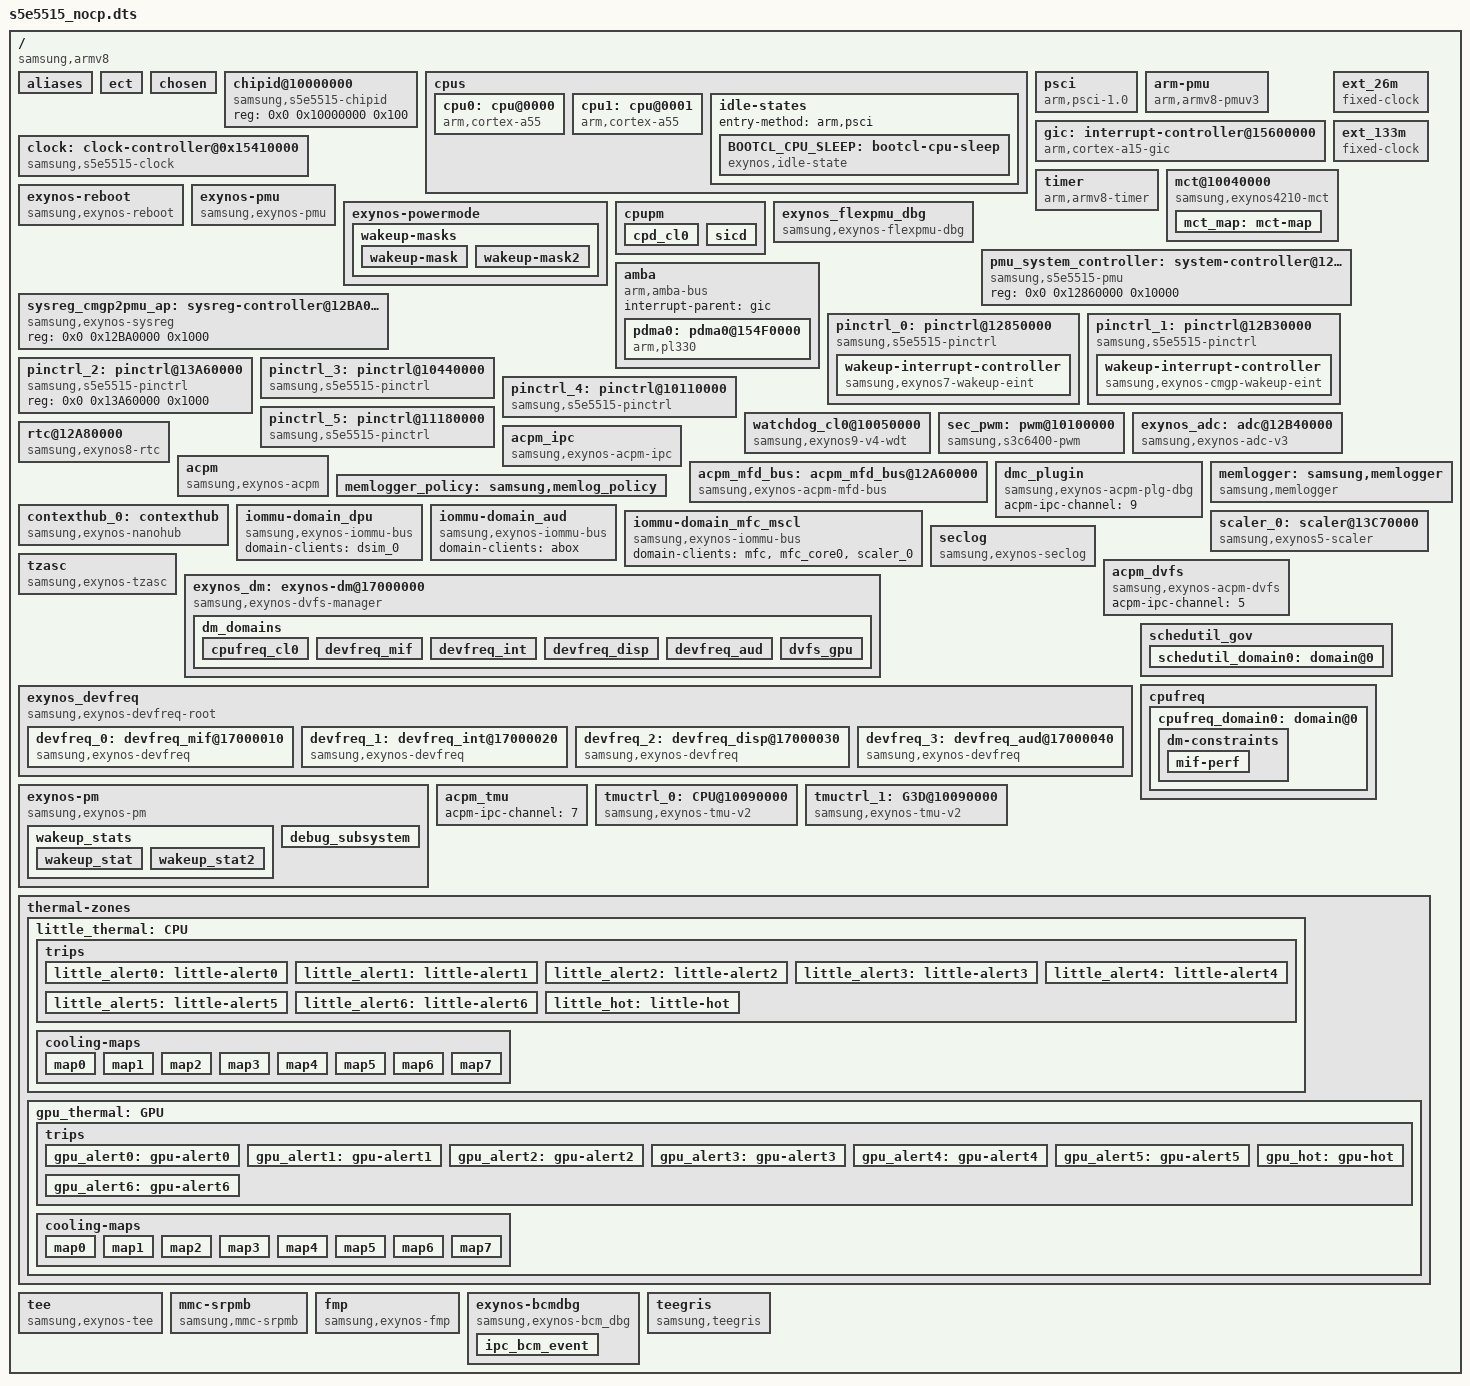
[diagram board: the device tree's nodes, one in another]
/*
 * SAMSUNG EXYNOS5515 SoC device tree source
 *
 * Copyright (c) 2017 Samsung Electronics Co., Ltd.
 *		http://www.samsung.com
 *
 * SAMSUNG EXYNOS5515 SoC device nodes are listed in this file.
 * EXYNOS5515 based board files can include this file and provide
 * values for board specfic bindings.
 *
 * This program is free software; you can redistribute it and/or modify
 * it under the terms of the GNU General Public License version 2 as
 * published by the Free Software Foundation.
 */
/dts-v1/;

#include "s5e5515-rmem_nocp.dtsi"
#include <dt-bindings/clock/s5e5515.h>
#include <dt-bindings/soc/samsung/exynos-bcm_dbg.h>
#include <dt-bindings/soc/samsung/s5e5515-dm.h>
#include <dt-bindings/soc/samsung/s5e5515-devfreq.h>
#include <dt-bindings/interrupt-controller/arm-gic.h>
#include <dt-bindings/interrupt-controller/s5e5515.h>
#include "s5e5515-dpu.dtsi"
#include "s5e5515-pinctrl.dtsi"
#include "s5e5515-usi.dtsi"
#include "s5e5515-usb.dtsi"
#include "s5e5515-sysmmu.dtsi"
#include "s5e5515-pm-domains.dtsi"
#include "s5e5515-mali.dtsi"
#include "s5e5515-audio.dtsi"
#include "s5e5515-debug.dtsi"
#include "s5e5515-mfc.dtsi"
#include "s5e5515-bts.dtsi"
#include "s5e5515-mmc.dtsi"
#include "s5e5515-lpd.dtsi"

/ {
	compatible = "samsung,armv8", "samsung,s5e5515";
	dtb-hw_rev = <0>;
	dtb-hw_rev_end = <255>;
	interrupt-parent = <&gic>;
	#address-cells = <2>;
	#size-cells = <1>;

	aliases {
		pinctrl0 = &pinctrl_0;
		pinctrl1 = &pinctrl_1;
		pinctrl2 = &pinctrl_2;
		pinctrl3 = &pinctrl_3;
		pinctrl4 = &pinctrl_4;
		pinctrl5 = &pinctrl_5;
		contexthub0 = &contexthub_0;

		scaler0 = &scaler_0;
	};

	ect {
		parameter_address = <0x90000000>;
		parameter_size = <0x32000>;
	};

	chosen: chosen {
		bootargs = "console=ram clocksource=arch_sys_counter clk_ignore_unused of_devlink=0 androidboot.hardware=s5e5515 firmware_class.path=/vendor/firmware androidboot.boot_devices=10500000.dwmmc0 sec_debug.cp=3 reserve-bcm=0xffffff80f8e00000 s3c2410_wdt.tmr_atboot=1 s3c2410_wdt.tmr_margin=80 rcupdate.rcu_expedited=1";
		linux,initrd-start = <0x84000000>;
		linux,initrd-end = <0x841FFFFF>;
	};

	chipid@10000000 {
		compatible = "samsung,s5e5515-chipid";
		reg = <0x0 0x10000000 0x100>;
	};

	cpus {
		#address-cells = <2>;
		#size-cells = <0>;

		cpu0: cpu@0000 {
			device_type = "cpu";
			compatible = "arm,cortex-a55", "arm,armv8";
			reg = <0x0 0x0000>;
			enable-method = "psci";
			cpu-idle-states = <&BOOTCL_CPU_SLEEP>;
		};
		cpu1: cpu@0001 {
			device_type = "cpu";
			compatible = "arm,cortex-a55", "arm,armv8";
			reg = <0x0 0x0001>;
			enable-method = "psci";
			cpu-idle-states = <&BOOTCL_CPU_SLEEP>;
		};

		idle-states {
			entry-method = "arm,psci";

			BOOTCL_CPU_SLEEP: bootcl-cpu-sleep {
				idle-state-name = "c2";
				compatible = "exynos,idle-state";
				arm,psci-suspend-param = <0x0010000>;
				entry-latency-us = <35>;
				exit-latency-us = <90>;
				min-residency-us = <750>;
				status = "okay";
			};
		};
	};

	psci {
		compatible = "arm,psci-1.0";
		method = "smc";
		cpu_suspend = <0xC4000001>;
		cpu_off = <0x84000002>;
		cpu_on = <0xC4000003>;
	};

	arm-pmu {
		compatible = "arm,armv8-pmuv3";
		interrupts = <0 INTREQ__CPUCL0_PMUIRQ_0 4>,
			      <0 INTREQ__CPUCL0_PMUIRQ_1 4>;
		interrupt-affinity = <&cpu0>, <&cpu1>;
	};

	gic:interrupt-controller@15600000 {
		compatible = "arm,cortex-a15-gic", "arm,cortex-a9-gic";
		#interrupt-cells = <3>;
		#address-cells = <0>;
		interrupt-controller;
		reg =	<0x0 0x15601000 0x1000>,
			<0x0 0x15602000 0x1000>,
			<0x0 0x15604000 0x2000>,
			<0x0 0x15606000 0x2000>;
	};

	clock: clock-controller@0x15410000 {
	       compatible = "samsung,s5e5515-clock";
	       reg = <0x0 0x15410000 0x8000>;
		#clock-cells = <1>;
		acpm-ipc-channel = <0>;
	};

	ext_26m: ext_26m {
		compatible = "fixed-clock";
		#clock-cells = <0>;
		clock-frequency = <26000000>;
		clock-output-names = "ext-26m";
	};

	ext_133m: ext_133m {
		compatible = "fixed-clock";
		#clock-cells = <0>;
		clock-frequency = <133250000>;
		clock-output-names = "ext-133m";
	};

	timer {
		compatible = "arm,armv8-timer";
		interrupts = <GIC_PPI 13
				(GIC_CPU_MASK_SIMPLE(8) | IRQ_TYPE_LEVEL_LOW)>,
			     <GIC_PPI 14
				(GIC_CPU_MASK_SIMPLE(8) | IRQ_TYPE_LEVEL_LOW)>,
			     <GIC_PPI 11
				(GIC_CPU_MASK_SIMPLE(8) | IRQ_TYPE_LEVEL_LOW)>,
			     <GIC_PPI 10
				(GIC_CPU_MASK_SIMPLE(8) | IRQ_TYPE_LEVEL_LOW)>;
	        clock-frequency = <26000000>;
	};

	mct@10040000 {
		compatible = "samsung,exynos4210-mct";
		reg = <0x0 0x10040000 0x800>;
		interrupt-controller;
		#interrupt-cells = <1>;
		interrupt-parent = <&mct_map>;
		interrupts =	<0>, <1>, <2>, <3>,
				<4>, <5>, <6>, <7>,
				<8>, <9>, <10>, <11>;
		clocks = <&clock OSCCLK>, <&clock GATE_MCT>;
		clock-names = "fin_pll", "mct";

		mct_map: mct-map {
			#interrupt-cells = <1>;
			#address-cells = <0>;
			#size-cells = <0>;
			interrupt-map = <0 &gic 0 INTREQ__MCT_G0 IRQ_TYPE_LEVEL_HIGH>,
					<1 &gic 0 INTREQ__MCT_G1 IRQ_TYPE_LEVEL_HIGH>,
					<2 &gic 0 INTREQ__MCT_G2 IRQ_TYPE_LEVEL_HIGH>,
					<3 &gic 0 INTREQ__MCT_G3 IRQ_TYPE_LEVEL_HIGH>,
					<4 &gic 0 INTREQ__MCT_L0 IRQ_TYPE_LEVEL_HIGH>,
					<5 &gic 0 INTREQ__MCT_L1 IRQ_TYPE_LEVEL_HIGH>,
					<6 &gic 0 INTREQ__MCT_L2 IRQ_TYPE_LEVEL_HIGH>,
					<7 &gic 0 INTREQ__MCT_L3 IRQ_TYPE_LEVEL_HIGH>,
					<8 &gic 0 INTREQ__MCT_L4 IRQ_TYPE_LEVEL_HIGH>,
					<9 &gic 0 INTREQ__MCT_L5 IRQ_TYPE_LEVEL_HIGH>,
					<10 &gic 0 INTREQ__MCT_L6 IRQ_TYPE_LEVEL_HIGH>,
					<11 &gic 0 INTREQ__MCT_L7 IRQ_TYPE_LEVEL_HIGH>;
		};
	};

	exynos-reboot {
		compatible = "samsung,exynos-reboot";
		samsung,syscon-phandle = <&pmu_system_controller>;
		shutdown-offset = <0x30C>;
		shutdown-trigger = <0x100>;
		reboot-offset = <0x3d00>;
		reboot-trigger = <0x2>;
		reboot-cmd-offset = <0x0810>;
	};

	exynos-pmu {
		compatible = "samsung,exynos-pmu";
		samsung,syscon-phandle = <&pmu_system_controller>;
		reg = <0x0 0x12860000 0x10000>;
		reg-names = "pmu_alive";
	};

	exynos-powermode {
		wakeup-masks {
			/*
			 * wakeup_mask configuration (Only SICD use wakeup-mask)
			 *      SICD          SICD_CPD      AFTR          STOP
			 *      LPD           LPA           ALPA          DSTOP
			 *      SLEEP         SLEEP_VTS_ON  SLEEP_AUD_ON  FAPO
			 *      USB_L2        SYS_SLEEP_HSI2ON
			 */
			wakeup-mask {
				mask = <0x07F3BFFF>, <0x0>,        <0x0>,        <0x0>,
				       <0x0>,        <0x0>,        <0x0>,        <0x0>,
				       <0x0>,        <0x0>,        <0x0>,        <0x0>,
				       <0x0>,        <0x0>;
				reg-offset = <0x3C44>;
			};
			wakeup-mask2 {
				mask = <0x00666807>, <0x0>,        <0x0>,        <0x0>,
				       <0x0>,        <0x0>,        <0x0>,        <0x0>,
				       <0x0>,        <0x0>,        <0x0>,        <0x0>,
				       <0x0>,        <0x0>;
				reg-offset = <0x3C64>;
			};
		};
	};

	cpupm {
		#define POWERMODE_TYPE_CLUSTER  0
		#define POWERMODE_TYPE_SYSTEM   1

		cpd_cl0 {
			device_type = "cpupm";
			target-residency = <3000>;
			psci-index = <128>;
			type = <POWERMODE_TYPE_CLUSTER>;
			siblings = "0-1";
		};

		sicd {
			device_type = "cpupm";
			target-residency = <3000>;
			psci-index = <256>;
			type = <POWERMODE_TYPE_SYSTEM>;
			siblings = "0-1";
			entry-allowed = "0-1";
			system-idle;
		};
	};

	exynos_flexpmu_dbg {
		compatible = "samsung,exynos-flexpmu-dbg";
		#address-cells = <2>;
		#size-cells = <1>;
		data-base = <0x12D1FB00>;
		data-size = <0x400>;
		mid-dvs-en = <0>;
		reg = <0x0 0x12a80000 0x1000>;
	};

	pmu_system_controller: system-controller@12860000 {
	       compatible = "samsung,s5e5515-pmu", "syscon";
	       reg = <0x0 0x12860000 0x10000>;
       };

	sysreg_cmgp2pmu_ap: sysreg-controller@12BA0000 {
		compatible = "samsung,exynos-sysreg", "syscon";
		reg = <0x0 0x12BA0000 0x1000>;
	};

	/* DMA */
	amba {
		#address-cells = <2>;
		#size-cells = <1>;
		compatible = "arm,amba-bus";
		interrupt-parent = <&gic>;
		ranges;

		pdma0: pdma0@154F0000 {
			compatible = "arm,pl330", "arm,primecell";
			reg = <0x0 0x154F0000 0x1000>;
			interrupts = <0 INTREQ__PDMA_irq_u1 IRQ_TYPE_LEVEL_HIGH>;
			clocks = <&clock GATE_PDMA_CORE_QCH>;
			clock-names = "apb_pclk";
			#dma-cells = <1>;
			#dma-channels = <4>;
			#dma-requests = <32>;
			#dma-multi-irq = <1>;
			dma-arwrapper = <0x154F4400>,
					<0x154F4420>,
					<0x154F4440>,
					<0x154F4460>;
			dma-awwrapper = <0x154F4404>,
					<0x154F4424>,
					<0x154F4444>,
					<0x154F4464>;
			dma-instwrapper = <0x154F4480>;
			dma-mask-bit = <36>;
			coherent-mask-bit = <36>;
		};
	};

	/* ALIVE */
	pinctrl_0: pinctrl@12850000 {
		compatible = "samsung,s5e5515-pinctrl";
		reg = <0x0 0x12850000 0x1000>;
		interrupts =  <0 INTREQ__ALIVE_EXT_INT0 IRQ_TYPE_LEVEL_HIGH>,
						<0 INTREQ__ALIVE_EXT_INT1 IRQ_TYPE_LEVEL_HIGH>,
						<0 INTREQ__ALIVE_EXT_INT2 IRQ_TYPE_LEVEL_HIGH>,
						<0 INTREQ__ALIVE_EXT_INT3 IRQ_TYPE_LEVEL_HIGH>,
						<0 INTREQ__ALIVE_EXT_INT4 IRQ_TYPE_LEVEL_HIGH>,
						<0 INTREQ__ALIVE_EXT_INT5 IRQ_TYPE_LEVEL_HIGH>,
						<0 INTREQ__ALIVE_EXT_INT6 IRQ_TYPE_LEVEL_HIGH>,
						<0 INTREQ__ALIVE_EXT_INT7 IRQ_TYPE_LEVEL_HIGH>,
						<0 INTREQ__ALIVE_EXT_INT8 IRQ_TYPE_LEVEL_HIGH>,
						<0 INTREQ__ALIVE_EXT_INT9 IRQ_TYPE_LEVEL_HIGH>,
						<0 INTREQ__ALIVE_EXT_INT10 IRQ_TYPE_LEVEL_HIGH>,
						<0 INTREQ__ALIVE_EXT_INT11 IRQ_TYPE_LEVEL_HIGH>,
						<0 INTREQ__ALIVE_EXT_INT12 IRQ_TYPE_LEVEL_HIGH>,
						<0 INTREQ__ALIVE_EXT_INT13 IRQ_TYPE_LEVEL_HIGH>,
						<0 INTREQ__ALIVE_EXT_INT14 IRQ_TYPE_LEVEL_HIGH>;

		wakeup-interrupt-controller {
			compatible = "samsung,exynos7-wakeup-eint";
		};

	};

	/* CMGP_ALIVE */
	pinctrl_1: pinctrl@12B30000{
		compatible = "samsung,s5e5515-pinctrl";
		reg = <0x0 0x12B30000 0x1000>;
		interrupts = <0 INTREQ__CMGP_EXT_INTM00 IRQ_TYPE_LEVEL_HIGH>,
					<0 INTREQ__CMGP_EXT_INTM01 IRQ_TYPE_LEVEL_HIGH>,
					<0 INTREQ__CMGP_EXT_INTM02 IRQ_TYPE_LEVEL_HIGH>,
					<0 INTREQ__CMGP_EXT_INTM03 IRQ_TYPE_LEVEL_HIGH>,
					<0 INTREQ__CMGP_EXT_INTM04 IRQ_TYPE_LEVEL_HIGH>,
					<0 INTREQ__CMGP_EXT_INTM05 IRQ_TYPE_LEVEL_HIGH>,
					<0 INTREQ__CMGP_EXT_INTM06 IRQ_TYPE_LEVEL_HIGH>,
					<0 INTREQ__CMGP_EXT_INTM07 IRQ_TYPE_LEVEL_HIGH>,
					<0 INTREQ__CMGP_EXT_INTM08 IRQ_TYPE_LEVEL_HIGH>,
					<0 INTREQ__CMGP_EXT_INTM09 IRQ_TYPE_LEVEL_HIGH>,
					<0 INTREQ__CMGP_EXT_INTM10 IRQ_TYPE_LEVEL_HIGH>,
					<0 INTREQ__CMGP_EXT_INTM11 IRQ_TYPE_LEVEL_HIGH>,
					<0 INTREQ__CMGP_EXT_INTM12 IRQ_TYPE_LEVEL_HIGH>,
					<0 INTREQ__CMGP_EXT_INTM13 IRQ_TYPE_LEVEL_HIGH>,
					<0 INTREQ__CMGP_EXT_INTM14 IRQ_TYPE_LEVEL_HIGH>,
					<0 INTREQ__CMGP_EXT_INTM15 IRQ_TYPE_LEVEL_HIGH>,
					<0 INTREQ__CMGP_EXT_INTM16 IRQ_TYPE_LEVEL_HIGH>,
					<0 INTREQ__CMGP_EXT_INTM17 IRQ_TYPE_LEVEL_HIGH>,
					<0 INTREQ__CMGP_EXT_INTM18 IRQ_TYPE_LEVEL_HIGH>,
					<0 INTREQ__CMGP_EXT_INTM19 IRQ_TYPE_LEVEL_HIGH>,
					<0 INTREQ__CMGP_EXT_INTM20 IRQ_TYPE_LEVEL_HIGH>,
					<0 INTREQ__CMGP_EXT_INTM21 IRQ_TYPE_LEVEL_HIGH>,
					<0 INTREQ__CMGP_EXT_INTM22 IRQ_TYPE_LEVEL_HIGH>,
					<0 INTREQ__CMGP_EXT_INTM23 IRQ_TYPE_LEVEL_HIGH>,
					<0 INTREQ__CMGP_EXT_INTM24 IRQ_TYPE_LEVEL_HIGH>,
					<0 INTREQ__CMGP_EXT_INTM25 IRQ_TYPE_LEVEL_HIGH>,
					<0 INTREQ__CMGP_EXT_INTM26 IRQ_TYPE_LEVEL_HIGH>;

		samsung,syscon-phandle = <&sysreg_cmgp2pmu_ap>;
		wakeup-interrupt-controller {
			compatible = "samsung,exynos-cmgp-wakeup-eint";
		};
	};

	/* DPU */
	pinctrl_2: pinctrl@13A60000{
		compatible = "samsung,s5e5515-pinctrl";
		reg = <0x0 0x13A60000 0x1000>;
	};

	/* FSYS */
	pinctrl_3: pinctrl@10440000 {
		compatible = "samsung,s5e5515-pinctrl";
		reg = <0x0 0x10440000 0x1000>;
		interrupts = <0 INTREQ__GPIO_FSYS IRQ_TYPE_LEVEL_HIGH>;
	};

	/* PERI */
	pinctrl_4: pinctrl@10110000 {
		compatible = "samsung,s5e5515-pinctrl";
		reg = <0x0 0x10110000 0x1000>;
		interrupts = <0 INTREQ__GPIO_PERI IRQ_TYPE_LEVEL_HIGH>;
	};

	/* VTS */
	pinctrl_5: pinctrl@11180000{
		compatible = "samsung,s5e5515-pinctrl";
		reg = <0x0 0x11180000 0x1000>;
		interrupts = <0 GPIO_INTREQ_VTS IRQ_TYPE_LEVEL_HIGH>;
	};

	watchdog_cl0@10050000 {
		compatible = "samsung,exynos9-v4-wdt";
		reg = <0x0 0x10050000 0x100>;
		interrupts = <0 INTREQ__WDT0 IRQ_TYPE_LEVEL_HIGH>;
		clocks = <&clock OSCCLK>, <&clock GATE_WDT_CLUSTER0>;
		clock-names = "rate_watchdog", "gate_watchdog";
		timeout-sec = <30>;
		shutdown_wdt_timeout = <30>;
		samsung,syscon-phandle = <&pmu_system_controller>;
		index = <0>; /* if little cluster then index is 0 */
		status = "okay";
	};

	sec_pwm: pwm@10100000 {
		compatible = "samsung,s3c6400-pwm";
		reg = <0x0 0x10100000 0x1000>;
		samsung,pwm-outputs = <0>, <1>, <2>, <3>, <4>;
		#pwm-cells = <3>;
		clocks = <&clock GATE_PWM_MOTOR>, <&clock OSCCLK>;
		clock-names = "pwm_pclk", "pwm_sclk";
		status = "okay";
	};

	exynos_adc: adc@12B40000 {
		compatible = "samsung,exynos-adc-v3";
		reg = <0x0 0x12B40000 0x100>;
		interrupts = <0 INTREQ__ADC_CMGP2AP IRQ_TYPE_LEVEL_HIGH>;
		#io-channel-cells = <1>;
		io-channel-ranges;
		clocks = <&clock GATE_ADC_CMGP_S0>;
		clock-names = "gate_adcif";
	};

	rtc@12A80000 {
		compatible = "samsung,exynos8-rtc";
		reg = <0x0 0x12A80000 0x100>;
		interrupts = <0 INTREQ__RTC_ALARM_INT IRQ_TYPE_LEVEL_HIGH>, <0 INTREQ__RTC_TIC_INT_0 IRQ_TYPE_LEVEL_HIGH>;
	};

	acpm_ipc {
		compatible = "samsung,exynos-acpm-ipc";
		#address-cells = <2>;
		#size-cells = <1>;
		interrupts = <GIC_SPI INTREQ__MAILBOX_APM2AP IRQ_TYPE_LEVEL_HIGH>;	/* AP2APM MAILBOX SPI NUM*/
		reg = <0x0 0x12900000 0x1000>,		/* AP2APM MAILBOX */
			<0x0 0x12D00000 0x22000>;	/* APM SRAM */
		initdata-base = <0x6900>;		/* AP share */
		num-timestamps = <32>;
		debug-log-level = <0>;
		logging-period = <500>;
		dump-base = <0x12D03000>;
		dump-size = <0x1F000>;			/* 136KB - 12KB(SACPM) = 124KB */
		dram-dump-base = <0x90009000>;
	};

	acpm {
		compatible = "samsung,exynos-acpm";
		#address-cells = <2>;
		#size-cells = <1>;
		acpm-ipc-channel = <4>;
		use-plugin-library;
		fvmap_offset = <0x20000>;		/* FVMAP: 0x20000*/
		reg = <0x0 0x12830000 0x1000>;		/* TIMER_APM */
		reg-names = "timer_apm";
		peritimer-cnt = <0xFFFF>;
	};

	acpm_mfd_bus: acpm_mfd_bus@12A60000 {
		compatible = "samsung,exynos-acpm-mfd-bus";
		status = "okay";
	};

	dmc_plugin {
		compatible = "samsung,exynos-acpm-plg-dbg";
		acpm-ipc-channel = <9>;
	};

	memlogger: samsung,memlogger {
		compatible = "samsung,memlogger";
		memory-region = <&memlog_mem>;
		samsung,bl-node = <&memlog_bl_base>;
	};

	memlogger_policy: samsung,memlog_policy {
		samsung,log-level = <4>;
		samsung,file-default-status = <1>;
		samsung,mem-constraint = <0>;
		samsung,mem-to-file-allow = <1>;
	};

	contexthub_0: contexthub {
		compatible = "samsung,exynos-nanohub";
		memory-region = <&chub_rmem &lpd_rmem>;
		/* INTREQ MAILBOX_AP2CHUB */
		interrupts = <0 58 IRQ_TYPE_LEVEL_HIGH>, <0 87 IRQ_TYPE_LEVEL_HIGH>;
		reg =	<0x0 0x12A30000 0x200>,
		        <0x0 0x12A20000 0x200>,
			<0x0 0x10D00000 0x200000>,
			<0x0 0x10CD0000 0x100>,
			<0x0 0x12863300 0x10>,
			<0x0 0x10C20000 0x20>,
			<0x0 0x10C30000 0x20>,
			<0x0 0x10C40000 0x4000>,
			<0x0 0x10110000 0x2000>;
			/*<0x0 0x10C00000 0x1820>,
			<0x0 0x10C40000 0x3030>,
			<0x0 0x10C70000 0x10>,
			<0x0 0x10C60000 0x10>,
			<0x0 0x10C90000 0x50>,
			<0x0 0x10CA0000 0xF0>,
			<0x0 0x10CB0000 0xF0>,
			<0x0 0x10CC0000 0xF0>;*/
		reg-names = "mailbox", "mailbox_apm_chub", "sram", "dumpgpr", "chub_reset",
			    "baaw_c_chub", "baaw_d_chub", "sysreg_chub", "gpio_peri";
			    /*"chub_dump_cmu", "chub_dump_sys",
			    "chub_dump_wdt", "chub_dump_timer",
			    "chub_dump_pwm", "chub_dump_usi0",
			    "chub_dump_usi1", "chub_dump_usi2";*/
		/* BAAW_C_CHUB to access mailbox, RTC, CMGP */
		baaw,baaw_c_chub = <0x40300 0x40800 0x12900 0x80000003>;
				   /* start    end    remap */
		baaw,baaw_d_chub = < 0x50000 0x50001 0x10000 0x80000003 /* chip id */
				     0x52860 0x52864 0x12860 0x80000003 /* APBIF */
				     0x53800 0x538F0 0x13800 0x80000003 /* SMMU */
				     0x53A60 0x53A70 0x13A60 0x80000003 /* GPIO_DPU */
				     0x50110 0x50112 0x10110 0x80000003 /* GPIO_PERI */
				     0x55410 0x55417 0x15410 0x80000003 /* CMU_TOP */
				   >;
		/* os-type default, multi-os, one-binary supported */
		os-type = "one-binary";
		/* chub dfs governer */
		chub-dfs-gov = "disabled";
	};

	iommu-domain_dpu {
		compatible = "samsung,exynos-iommu-bus";
		#address-cells = <2>;
		#size-cells = <1>;
		ranges;

		domain-clients = <&dsim_0>;
	};

	iommu-domain_aud {
		compatible = "samsung,exynos-iommu-bus";
		#address-cells = <2>;
		#size-cells = <1>;
		ranges;

		domain-clients = <&abox>;
	};

	iommu-domain_mfc_mscl {
		compatible = "samsung,exynos-iommu-bus";
		#address-cells = <2>;
		#size-cells = <1>;
		ranges;

		domain-clients = <&mfc>, <&mfc_core0>, <&scaler_0>;
	};

	scaler_0: scaler@13C70000 {
		compatible = "samsung,exynos5-scaler";
		reg = <0x0 0x13C70000 0x1400>;
		interrupts = <0 INTREQ__BL IRQ_TYPE_LEVEL_HIGH>;
		clocks = <&clock GATE_BL_QCH>;
		clock-names = "gate";
		iommus = <&sysmmu_mfcmscl>;
	};

	/* Secure Log */
	seclog {
		compatible = "samsung,exynos-seclog";
		interrupts = <GIC_SPI INTREQ__SECURE_LOG IRQ_TYPE_LEVEL_HIGH>;
	};

	tzasc {
		compatible = "samsung,exynos-tzasc";
		channel = <1>;
		tzc_ver = <380>;
		irqcnt = <1>;
		interrupts = <GIC_SPI INTREQ__DMC_INTR_MIF IRQ_TYPE_LEVEL_HIGH>;
	};

	exynos_dm: exynos-dm@17000000 {
		compatible = "samsung,exynos-dvfs-manager";
		reg = <0x0 0x17000000 0x0>;
		acpm-ipc-channel = <1>;
		dm_domains {
			cpufreq_cl0 {
				dm-index = <DM_CPU_CL0>;
				available = "true";
				cal_id = <ACPM_DVFS_CPUCL0>;
				dm_type_name = "dm_cpu_cl0";
			};
			devfreq_mif {
				dm-index = <DM_MIF>;
				available = "true";
				policy_use = "true";
				cal_id = <ACPM_DVFS_MIF>;
				dm_type_name = "dm_mif";
			};
			devfreq_int {
				dm-index = <DM_INT>;
				available = "true";
				policy_use = "true";
				cal_id = <ACPM_DVFS_INT>;
				dm_type_name = "dm_int";
			};
			devfreq_disp {
				dm-index = <DM_DISP>;
				available = "true";
				cal_id = <ACPM_DVFS_DISP>;
				dm_type_name = "dm_disp";
			};
			devfreq_aud {
				dm-index = <DM_AUD>;
				available = "true";
				cal_id = <ACPM_DVFS_AUD>;
				dm_type_name = "dm_aud";
			};
			dvfs_gpu {
				dm-index = <DM_GPU>;
				available = "false";
				cal_id = <ACPM_DVFS_G3D>;
				dm_type_name = "dm_gpu";
			};
		};
	};

	acpm_dvfs {
		compatible = "samsung,exynos-acpm-dvfs";
		acpm-ipc-channel = <5>;
	};

	exynos_devfreq {
		compatible = "samsung,exynos-devfreq-root";
		#address-cells = <2>;
		#size-cells = <1>;
		ranges;

		devfreq_0: devfreq_mif@17000010 {
			compatible = "samsung,exynos-devfreq";
			reg = <0x0 0x17000010 0x0>;
			devfreq_type = <DEVFREQ_MIF>;
			devfreq_domain_name = "MIF";
			pm_qos_class = <15>; /* PM_QOS_BUS_THROUGHPUT */
			pm_qos_class_max = <16>; /* PM_QOS_BUS_THROUGHPUT_MAX */
			dm-index = <DM_MIF>;

			/* Delay time */
			use_delay_time = "false";

			freq_info = <2093000 421000 1014000 421000 2093000 1539000>;
			/* initial_freq, default_qos, suspend_freq, min_freq, max_freq reboot_freq */

			/* Booting value */
			boot_info = <40 2093000>;
			/* boot_qos_timeout, boot_freq */

			/* governor data */
			governor = <SIMPLE_INTERACTIVE>;

			bts_update = "false";
			dfs_id = <ACPM_DVFS_MIF>;
			acpm-ipc-channel = <1>;
			use_acpm = "true";
		};

		devfreq_1: devfreq_int@17000020 {
			compatible = "samsung,exynos-devfreq";
			reg = <0x0 0x17000020 0x0>;
			devfreq_type = <DEVFREQ_INT>;
			devfreq_domain_name = "INT";
			pm_qos_class = <11>; /* PM_QOS_DEVICE_THROUGHPUT */
			pm_qos_class_max = <13>; /* PM_QOS_DEVICE_THROUGHPUT_MAX */
			dm-index = <DM_INT>;

			/* Delay time */
			use_delay_time = "false";

			freq_info = <533000 100000 100000 100000 533000 533000>;
			/* <initial_freq, default_qos, suspend_freq, min, max, reboot_freq> */

			/* Booting value */
			boot_info = <0 533000>;
			/* boot_qos_timeout, boot_freq */

			/* governor data */
			governor = <SIMPLE_INTERACTIVE>;

			bts_update = "false";
			dfs_id = <ACPM_DVFS_INT>;
			acpm-ipc-channel = <1>;
			use_acpm = "true";
		};

		devfreq_2: devfreq_disp@17000030 {
			compatible = "samsung,exynos-devfreq";
			reg = <0x0 0x17000030 0x0>;
			devfreq_type = <DEVFREQ_DISP>;
			devfreq_domain_name = "DISP";
			pm_qos_class = <19>; /* PM_QOS_DISPLAY_THROUGHPUT */
			pm_qos_class_max = <20>; /* PM_QOS_DISPLAY_THROUGHPUT_MAX */
			dm-index = <DM_DISP>;

			/* Delay time */
			use_delay_time = "false";

			freq_info = <267000 100000 1000000 100000 267000 267000>;
			/* <initial_freq, default_qos, suspend_freq, min, max, reboot_freq> */

			/* Booting value */
			boot_info = <0 267000>;
			/* boot_qos_timeout, boot_freq */

			/* governor data */
			governor = <SIMPLE_INTERACTIVE>;

			bts_update = "false";
			dfs_id = <ACPM_DVFS_DISP>;
		};

		devfreq_3: devfreq_aud@17000040 {
			compatible = "samsung,exynos-devfreq";
			reg = <0x0 0x17000040 0x0>;
			devfreq_type = <DEVFREQ_AUD>;
			devfreq_domain_name = "AUD";
			pm_qos_class = <22>; /* PM_QOS_AUD_THROUGHPUT */
			pm_qos_class_max = <27>; /* PM_QOS_AUD_THROUGHPUT_MAX */
			dm-index = <DM_AUD>;

			/* Delay time */
			use_delay_time = "false";

			freq_info = <200000 200000 200000 200000 1200000 200000>;
			/* <initial, default_qos, suspend_freq, min, max, reboot_freq> */

			/* Booting value */
			boot_info = <0 200000>;
			/* boot_qos_timeout, boot_freq */

			/* governor data */
			governor = <SIMPLE_INTERACTIVE>;

			bts_update = "false";
			dfs_id = <ACPM_DVFS_AUD>;
		};
	};

	schedutil_gov {
		schedutil_domain0: domain@0 {
			device_type = "schedutil-domain";
			shared-cpus = "0-1";

			enabled = <0>;		/* Disable */
			qos_min_class = <3>;
		};
	};

	cpufreq {
		cpufreq_domain0: domain@0 {
			device_type = "cpufreq-domain";
			sibling-cpus = "0-1";
			cal-id = <ACPM_DVFS_CPUCL0>;
			dm-type = <DM_CPU_CL0>;

			/* PM QoS Class ID*/
			pm_qos-min-class = <3>;
			pm_qos-max-class = <4>;

			#cooling-cells = <2>; /* min followed by max */

			dm-constraints {
				mif-perf {
					const-type = <CONSTRAINT_MIN>;
					dm-type = <DM_MIF>;
						/*  cpu     mif  */
					table = <  200000	0
						   300000	0
						   400000	0
						   533000  421000
						   667000  421000
						   800000  676000
						  1000000 1014000
						  1200000 2093000 >;
				};
			};
		 };
	};
	 exynos-pm {
		compatible = "samsung,exynos-pm";
		reg = <0x0 0x12850000 0x1000>,
			<0x0 0x15601200 0x100>,
			<0x0 0x12AB0000 0x2000>,
			<0x0 0x12A60000 0x1000>,
			<0x0 0x12B30000 0x1000>;
		reg-names = "gpio_alive_base",
			"gicd_ispendrn_base",
			 "sysreg_vgpio2pmu",
			 "i3c_base",
			 "gpio_cmgp_base";
		num-eint = <15>;		/* GPA0_0 - GPA0_7, GPA1_0 - GPA1-6*/
		num-cmgp-eint = <27>;		/* GPM00 - GPM26 */
		num-gic = <26>;
		suspend_mode_idx = <8>;         /* SYS_SLEEP */

		/* WAKEUP_STAT,      WAKEUP2_STAT*/
		wakeup_stat_offset = <0x3c50>,         <0x3c54>;
		wakeup_int_en_offset = <0x3c44>,         <0x3c64>;
		wakeup_int_en = <0x403BF6F>,         <0x7E2800>;
		eint_wakeup_mask_offset = <0x60C>;
		cmgp_eint_wakeup_mask_offset = <0x62c>;

		vgpio_wakeup_inten_offset = <0x288>;// check needed
		vgpio_wakeup_inten = <0x11>; // check needed

		wake_lock = <0>;		/* 1: held wake_lock */

		vgpio_tx_monitor = <0x0A14>; // check needed

		is_update_needed = <0x0>, <0x1>;
		gnss_status_offset = <0x3884>; // GNSS_STATUS
		wlbt_status_offset = <0x3904>; // WLBT_STATUS
		gnss_active_mask = <0x0>; // WAKEUP2_INT_EN__GNSS_ACTIVE
		wlbt_active_mask = <0x400>; // WAKEUP2_INT_EN__WLBT_ACTIVE
		wakeup_stats {
			wakeup_stat {
				ws-name =
					"RTC_ALARM",		/* [ 0] */
					"RTC_TICK",		/* [ 1] */
					"TRTC_ALARM",		/* [ 2] */
					"TRTC_TICK",		/* [ 3] */
					"RESERVED",		/* [ 4] */
					"CMGP2PMU_AP_EINT0",	/* [ 5] */
					"CMGP2PMU_AP_EINT1",	/* [ 6] */
					"MAILBOX_APM2AP",	/* [ 7] */
					"MAILBOX_CP2AP",	/* [ 8] */
					"MAILBOX_VTS2AP",	/* [ 9] */
					"S_MAILBOX_CP2AP",	/* [10] */
					"VTS_WDT",		/* [11] */
					"EINT",			/* [12] */
					"MAILBOX_GNSS2AP",	/* [13] */
					"MAILBOX_WLBT2AP",	/* [14] */
					"MAILBOX_CHUB2AP",	/* [15] */
					"REQUEST_CP",		/* [16] */
					"REQUEST_GNSS",		/* [17] */
					"REQUEST_WLBT",		/* [18] */
					"RESERVED",		/* [19] */
					"USBDP",		/* [20] */
					"MMC_CARD",		/* [21] */
					"MMC_EMBD",		/* [22] */
					"TIMER",		/* [23] */
					"CLUSTER0_CPU0_nIRQ",	/* [24] */
					"CLUSTER0_CPU1_nIRQ",	/* [25] */
					"MAILBOX_BT2AP",	/* [26] */
					"RESERVED",		/* [27] */
					"RESERVED",		/* [28] */
					"RESERVED",		/* [29] */
					"RESERVED",		/* [30] */
					"RESERVED";		/* [31] */
			};
			wakeup_stat2 {
				ws-name =
					"INTREQ__AUD_ABOX_GIC400",	/* [ 0] */
					"USB20_PHY_FS_VMINUX_WAKEUP",	/* [ 1] */
					"USB20_PHY_FS_VPLUS_WAKEUP",	/* [ 2] */
					"RESERVED",			/* [ 3] */
					"RESERVED",			/* [ 4] */
					"RESERVED",			/* [ 5] */
					"RESERVED",			/* [ 6] */
					"RESERVED",			/* [ 7] */
					"RESERVED",			/* [ 8] */
					"GNSS_ACTIVE",			/* [ 9] */
					"WLBT_ACTIVE",			/* [10] */
					"GNSS2APO_WAKEUP_INT_REQT",	/* [11] */
					"EINT_CMGP",			/* [12] */
					"CHUB_WDT",			/* [13] */
					"AUD_WDT",			/* [14] */
					"RESERVED",			/* [15] */
					"RESERVED",			/* [16] */
					"VGPIO2PMU_EINT0",		/* [17] */
					"VGPIO2PMU_EINT1",		/* [18] */
					"CMGP2PMU_CHUB_EINT0",		/* [19] */
					"CMGP2PMU_CHUB_EINT1",		/* [20] */
					"CHUG_CM55_WDT",		/* [21] */
					"TIMER",			/* [22] */
					"RESERVED",			/* [23] */
					"RESERVED",			/* [24] */
					"RESERVED",			/* [25] */
					"RESERVED",			/* [26] */
					"RESERVED",			/* [27] */
					"RESERVED",			/* [28] */
					"RESERVED",			/* [29] */
					"RESERVED",			/* [30] */
					"RESERVED";			/* [31] */
			};
		};
		debug_subsystem {
			sfr-name =
				"CP_OUT",
				"GNSS_OUT",
				"WLBT_OUT",
				"MIF_OUT",
				"CHUB_STATES";
			sfr-offset =
				<0x3820>,
				<0x38a0>,
				<0x3920>,
				<0x3B20>,
				<0x2108>;
		};
	};

	acpm_tmu {
		acpm-ipc-channel = <7>;
	};

	tmuctrl_0: CPU@10090000 {
		compatible = "samsung,exynos-tmu-v2";
		reg = <0x0 0x10070000 0x800>;
		interrupts = <GIC_SPI INTREQ__TMU IRQ_TYPE_LEVEL_HIGH>;
		tmu_name = "CPU";
		id = <0>;
		#thermal-sensor-cells = <0>;
	};

	tmuctrl_1: G3D@10090000 {
		compatible = "samsung,exynos-tmu-v2";
		reg = <0x0 0x10070000 0x800>;
		interrupts = <GIC_SPI INTREQ__TMU IRQ_TYPE_LEVEL_HIGH>;
		tmu_name = "G3D";
		id = <1>;
		#thermal-sensor-cells = <0>;
	};

	thermal-zones {
		little_thermal: CPU {
			zone_name  = "CPU_THERMAL";
			polling-delay-passive = <0>;
			polling-delay = <0>;
			thermal-sensors = <&tmuctrl_0>;

			trips {
				little_alert0: little-alert0 {
					temperature = <20000>; /* millicelsius */
					hysteresis = <5000>; /* millicelsius */
					type = "active";
				};
				little_alert1: little-alert1 {
					temperature = <76000>; /* millicelsius */
					hysteresis = <5000>; /* millicelsius */
					type = "active";
				};
				little_alert2: little-alert2 {
					temperature = <81000>; /* millicelsius */
					hysteresis = <5000>; /* millicelsius */
					type = "active";
				};
				little_alert3: little-alert3 {
					temperature = <86000>; /* millicelsius */
					hysteresis = <5000>; /* millicelsius */
					type = "active";
				};
				little_alert4: little-alert4 {
					temperature = <91000>; /* millicelsius */
					hysteresis = <5000>; /* millicelsius */
					type = "active";
				};
				little_alert5: little-alert5 {
					temperature = <96000>; /* millicelsius */
					hysteresis = <5000>; /* millicelsius */
					type = "active";
				};
				little_alert6: little-alert6 {
					temperature = <101000>; /* millicelsius */
					hysteresis = <5000>; /* millicelsius */
					type = "active";
				};
				little_hot: little-hot {
					temperature = <115000>; /* millicelsius */
					hysteresis = <5000>; /* millicelsius */
					type = "hot";
				};
			};
			cooling-maps {
				map0 {
					trip = <&little_alert0>;
					cooling-device = <&cpufreq_domain0 0 0>;
				};
				map1 {
					trip = <&little_alert1>;
					cooling-device = <&cpufreq_domain0 0 0>;
				};
				map2 {
					trip = <&little_alert2>;
					cooling-device = <&cpufreq_domain0 0 0>;
				};
				map3 {
					trip = <&little_alert3>;
					cooling-device = <&cpufreq_domain0 0 0>;
				};
				map4 {
					trip = <&little_alert4>;
					cooling-device = <&cpufreq_domain0 0 0>;
				};
				map5 {
					trip = <&little_alert5>;
					cooling-device = <&cpufreq_domain0 0 0>;
				};
				map6 {
					trip = <&little_alert6>;
					cooling-device = <&cpufreq_domain0 0 0>;
				};
				map7 {
					trip = <&little_hot>;
					cooling-device = <&cpufreq_domain0 0 0>;
				};
			};
		};

		gpu_thermal: GPU {
			zone_name  = "GPU_THERMAL";
			polling-delay-passive = <0>;
			polling-delay = <0>;
			thermal-sensors = <&tmuctrl_1>;

			trips {
				gpu_alert0: gpu-alert0 {
					temperature = <20000>; /* millicelsius */
					hysteresis = <5000>; /* millicelsius */
					type = "active";
				};
				gpu_alert1: gpu-alert1 {
					temperature = <76000>; /* millicelsius */
					hysteresis = <5000>; /* millicelsius */
					type = "active";
				};
				gpu_alert2: gpu-alert2 {
					temperature = <81000>; /* millicelsius */
					hysteresis = <5000>; /* millicelsius */
					type = "active";
				};
				gpu_alert3: gpu-alert3 {
					temperature = <86000>; /* millicelsius */
					hysteresis = <5000>; /* millicelsius */
					type = "active";
				};
				gpu_alert4: gpu-alert4 {
					temperature = <91000>; /* millicelsius */
					hysteresis = <5000>; /* millicelsius */
					type = "active";
				};
				gpu_alert5: gpu-alert5 {
					temperature = <96000>; /* millicelsius */
					hysteresis = <5000>; /* millicelsius */
					type = "active";
				};
				gpu_alert6: gpu-alert6 {
					temperature = <101000>; /* millicelsius */
					hysteresis = <5000>; /* millicelsius */
					type = "active";
				};
				gpu_hot: gpu-hot {
					temperature = <115000>; /* millicelsius */
					hysteresis = <5000>; /* millicelsius */
					type = "hot";
				};
			};

			cooling-maps {
				map0 {
				     trip = <&gpu_alert0>;
				     cooling-device = <&mali 0 0>;
				};
				map1 {
				     trip = <&gpu_alert1>;
				     cooling-device = <&mali 0 0>;
				};
				map2 {
				     trip = <&gpu_alert2>;
				     cooling-device = <&mali 0 0>;
				};
				map3 {
				     trip = <&gpu_alert3>;
				     cooling-device = <&mali 0 0>;
				};
				map4 {
				     trip = <&gpu_alert4>;
				     cooling-device = <&mali 0 0>;
				};
				map5 {
				     trip = <&gpu_alert5>;
				     cooling-device = <&mali 0 0>;
				};
				map6 {
				     trip = <&gpu_alert6>;
				     cooling-device = <&mali 0 0>;
				};
				map7 {
				     trip = <&gpu_hot>;
				     cooling-device = <&mali 0 0>;
				};
			};
		};
	};
	/* tbase */
	tee {
		compatible = "samsung,exynos-tee";
		interrupts = <GIC_SPI INTREQ__TBASE IRQ_TYPE_LEVEL_HIGH> ;
	};

	/* Secure RPMB */
	mmc-srpmb {
		compatible = "samsung,mmc-srpmb";
		interrupts = <GIC_SPI INTREQ__RPMB IRQ_TYPE_LEVEL_HIGH>;
	};

	/* Flash Memory Protector */
	fmp {
		compatible = "samsung,exynos-fmp";
	};

        exynos-bcmdbg {
                compatible = "samsung,exynos-bcm_dbg";
                memory-region = <&log_bcm>;

                pd-name = /*"pd-chub", "pd-gnss"*/ "pd-trex", "pd-disp", "pd-aud", "pd-g3d", "pd-mfc", "pd-vts", "pd-cpucl0",  "pd-fsys";

                max_define_event = <PRE_DEFINE_EVT_MAX>;
                /* define_event_index ev0 ev1 ev2 ev3 ev4 ev5 ev6 ev7 */
                define_events = <NO_PRE_DEFINE_EVT      0x0  0x0  0x0  0x0  0x0  0x0  0x0  0x0>,
                                <LATENCY_FMT_EVT        0x4  0x2  0x26 0x24 0x5  0x3  0x27 0x25>,
                                <MO_FMT_EVT             0x4  0x0  0x24 0x24 0x5  0x1  0x25 0x25>,
                                <BURST_LENGTH_FMT_EVT   0x4  0x2  0x4  0x26 0x5  0x3  0x5  0x27>,
                                <REQ_BLOCK_FMT_EVT      0x2  0x10 0x10 0x26 0x3  0x11 0x11 0x27>,
                                <DATA_BLOCK_FMT_EVT     0x4  0x12 0x12 0x6  0x5  0x13 0x13 0x14>,
                                <REQ_TYPE_FMT_EVT       0x2  0x15 0x18 0x1B 0x3  0x16 0x19 0x1C>,
                                <BCM_CALC_FMT_EVT       0x4  0x5  0x20 0x23 0x0  0x1  0x24 0x25>;
                default_define_event = <LATENCY_FMT_EVT>;

                /* sm_id_mask sm_id_value */
                define_filter_id = <NO_PRE_DEFINE_EVT   0x0  0x0>,
                                <LATENCY_FMT_EVT        0x0  0x0>,
                                <MO_FMT_EVT             0x0  0x0>,
                                <BURST_LENGTH_FMT_EVT   0x0  0x0>,
                                <REQ_BLOCK_FMT_EVT      0x0  0x0>,
                                <DATA_BLOCK_FMT_EVT     0x0  0x0>,
                                <REQ_TYPE_FMT_EVT       0x0  0x0>,
                                <BCM_CALC_FMT_EVT       0x0  0x0>;
                /* ev0 ev1 ev2 ev3 ev4 ev5 ev6 ev7 */
                define_filter_id_active = <NO_PRE_DEFINE_EVT    0x0  0x0  0x0  0x0  0x0  0x0  0x0  0x0>,
                                        <LATENCY_FMT_EVT        0x0  0x0  0x0  0x0  0x0  0x0  0x0  0x0>,
                                        <MO_FMT_EVT             0x0  0x0  0x0  0x0  0x0  0x0  0x0  0x0>,
                                        <BURST_LENGTH_FMT_EVT   0x0  0x0  0x0  0x0  0x0  0x0  0x0  0x0>,
                                        <REQ_BLOCK_FMT_EVT      0x0  0x0  0x0  0x0  0x0  0x0  0x0  0x0>,
                                        <DATA_BLOCK_FMT_EVT     0x0  0x0  0x0  0x0  0x0  0x0  0x0  0x0>,
                                        <REQ_TYPE_FMT_EVT       0x0  0x0  0x0  0x0  0x0  0x0  0x0  0x0>,
                                        <BCM_CALC_FMT_EVT       0x0  0x0  0x0  0x0  0x0  0x0  0x0  0x0>;
                /* sm_other_type0 sm_other_mask0 sm_other_value0 */
                define_filter_other_0 = <NO_PRE_DEFINE_EVT      0x0  0x0  0x0>,
                                        <LATENCY_FMT_EVT        0x0  0x0  0x0>,
                                        <MO_FMT_EVT             0x0  0x0  0x0>,
                                        <BURST_LENGTH_FMT_EVT   0x0  0x0  0x0>,
                                        <REQ_BLOCK_FMT_EVT      0x0  0x0  0x0>,
                                        <DATA_BLOCK_FMT_EVT     0x0  0x0  0x0>,
                                        <REQ_TYPE_FMT_EVT       0x0  0x0  0x0>,
                                        <BCM_CALC_FMT_EVT       0x0  0x0  0x0>;
                /* sm_other_type1 sm_other_mask1 sm_other_value1 */
                define_filter_other_1 = <NO_PRE_DEFINE_EVT      0x0  0x0  0x0>,
                                        <LATENCY_FMT_EVT        0x0  0x0  0x0>,
                                        <MO_FMT_EVT             0x0  0x0  0x0>,
                                        <BURST_LENGTH_FMT_EVT   0x0  0x0  0x0>,
                                        <REQ_BLOCK_FMT_EVT      0x0  0x0  0x0>,
                                        <DATA_BLOCK_FMT_EVT     0x0  0x0  0x0>,
                                        <REQ_TYPE_FMT_EVT       0x0  0x0  0x0>,
                                        <BCM_CALC_FMT_EVT       0x0  0x0  0x0>;
                /* ev0 ev1 ev2 ev3 ev4 ev5 ev6 ev7 */
                define_filter_other_active = <NO_PRE_DEFINE_EVT 0x0  0x0  0x0  0x0  0x0  0x0  0x0  0x0>,
                                        <LATENCY_FMT_EVT        0x0  0x0  0x0  0x0  0x0  0x0  0x0  0x0>,
                                        <MO_FMT_EVT             0x0  0x0  0x0  0x0  0x0  0x0  0x0  0x0>,
                                        <BURST_LENGTH_FMT_EVT   0x0  0x0  0x0  0x0  0x0  0x0  0x0  0x0>,
                                        <REQ_BLOCK_FMT_EVT      0x0  0x0  0x0  0x0  0x0  0x0  0x0  0x0>,
                                        <DATA_BLOCK_FMT_EVT     0x0  0x0  0x0  0x0  0x0  0x0  0x0  0x0>,
                                        <REQ_TYPE_FMT_EVT       0x0  0x0  0x0  0x0  0x0  0x0  0x0  0x0>,
                                        <BCM_CALC_FMT_EVT       0x0  0x0  0x0  0x0  0x0  0x0  0x0  0x0>;

                /* peak_mask peak_id */
                define_sample_id = <NO_PRE_DEFINE_EVT   0x0  0x0>,
                                <LATENCY_FMT_EVT        0x0  0x0>,
                                <MO_FMT_EVT             0x0  0x0>,
                                <BURST_LENGTH_FMT_EVT   0x0  0x0>,
                                <REQ_BLOCK_FMT_EVT      0x0  0x0>,
                                <DATA_BLOCK_FMT_EVT     0x0  0x0>,
                                <REQ_TYPE_FMT_EVT       0x0  0x0>,
                                <BCM_CALC_FMT_EVT       0x0  0x0>;
                /* ev0 ev1 ev2 ev3 ev4 ev5 ev6 ev7 */
                define_sample_id_enable = <NO_PRE_DEFINE_EVT    0x0  0x0  0x0  0x0  0x0  0x0  0x0  0x0>,
                                        <LATENCY_FMT_EVT        0x0  0x0  0x1  0x0  0x0  0x0  0x1  0x0>,
                                        <MO_FMT_EVT             0x0  0x0  0x1  0x0  0x0  0x0  0x1  0x0>,
                                        <BURST_LENGTH_FMT_EVT   0x0  0x0  0x1  0x1  0x0  0x0  0x1  0x1>,
                                        <REQ_BLOCK_FMT_EVT      0x0  0x0  0x1  0x1  0x0  0x0  0x1  0x1>,
                                        <DATA_BLOCK_FMT_EVT     0x0  0x0  0x1  0x0  0x0  0x0  0x1  0x0>,
                                        <REQ_TYPE_FMT_EVT       0x0  0x0  0x0  0x0  0x0  0x0  0x0  0x0>,
                                        <BCM_CALC_FMT_EVT       0x0  0x0  0x0  0x0  0x0  0x0  0x0  0x0>;

                bcm_cnt_nr = <8>;
                bcm_ip_nr = <18>;
                bcm_ip_print_nr = <10>;
                initial_run_bcm_ip = <0>, <1>, <2>, <3>, <4>, <5>, <6>, <7>, <8>, <9>, <10>,
                                <11>, <12>, <13>, <14>, <15>, <16>, <17>;
                initial_bcm_run = <BCM_STOP>;
                /* msec (max 500msec) */
                initial_period = <1>;
                initial_bcm_mode = <BCM_MODE_INTERVAL>;
                available_stop_owner = <PANIC_HANDLE CAMERA_DRIVER MODEM_IF ITMON_HANDLE>;
                buff_size = <0x200000>;
                glb_auto_en = <0>;

                /* profiler infomation */
                bcm_calc_num_ip = <4>;
                bcm_calc_ip_idx = <1>, <3>, <62>, <67>;
                bcm_calc_ip_name = "CPUCL0_0", "G3D0", "IRPS0", "MIF0";
                bcm_calc_ip_cnt = <2>, <4>, <4>, <4>;
                bcm_calc_bus_width = <32>, <16>, <32>, <16>;
                bcm_calc_sample_time = <50>;
                perf_define_event = <BCM_CALC_FMT_EVT>;

                ipc_bcm_event {
                        plugin-len = <5>;
                        plugin-name = "BCM";
                };
        };

	/* TEEGRIS */
	teegris {
		compatible = "samsung,teegris";
		interrupts = <GIC_SPI INTREQ__TEEGRIS_EVENT IRQ_TYPE_LEVEL_HIGH>,
		             <GIC_SPI INTREQ__TEEGRIS_PANIC IRQ_TYPE_LEVEL_HIGH>;
	};
};
